AUTOSAR XML (schema 4-0-3)
standard types defined: Boolean, UInt8
package /AUTOSAR_Platform/DataConstrs
  range DC_Boolean: raw 0..1
  range DC_UInt8: raw 0..255
package /PATAC/EEPROM/BaseData
  base type PJB_EEP_Uint8: category=FIXED_LENGTH, base-type-size=8, base-type-encoding=NONE, native-declaration=unsigned char
package /PATAC/EEPROM/ImplementationDataType
  impl type EEP_Uint8: category=VALUE, base-type=PJB_EEP_Uint8, sw-calibration-access=READ-ONLY, type-emitter=RTE
package /PATAC/MSM/ComponentTypes
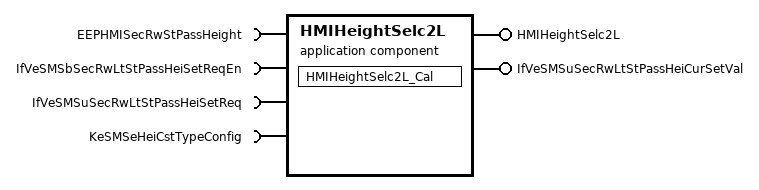
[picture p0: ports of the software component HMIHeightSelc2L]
  application sw component type HMIHeightSelc2L
    provide port HMIHeightSelc2L: server-com-spec{operation=Cal, queue-length=1}, provided-interface=HMIHeightSelc2L
    provide port IfVeSMSuSecRwLtStPassHeiCurSetVal: nonqueued-sender-com-spec{data-element=IfVeSMSuSecRwLtStPassHeiCurSetVal/Val, init-value=0}, provided-interface=IfVeSMSuSecRwLtStPassHeiCurSetVal
    4 x require port:
      EEPHMISecRwStPassHeight: required-com-specs=[Get, Set], required-interface=EEPHMISecRwStPassHeight
      IfVeSMSbSecRwLtStPassHeiSetReqEn: nonqueued-receiver-com-spec{data-element=IfVeSMSbSecRwLtStPassHeiSetReqEn/Val, filter=data-filter-type=ALWAYS, init-value=0}, required-interface=IfVeSMSbSecRwLtStPassHeiSetReqEn
      IfVeSMSuSecRwLtStPassHeiSetReq: nonqueued-receiver-com-spec{data-element=IfVeSMSuSecRwLtStPassHeiSetReq/Val, filter=data-filter-type=ALWAYS, init-value=0}, required-interface=IfVeSMSuSecRwLtStPassHeiSetReq
      KeSMSeHeiCstTypeConfig: parameter-require-com-spec{init-value=0, parameter=Val}, required-interface=KeSMSeHeiCstTypeConfig
    behavior HMIHeightSelc2L_InternalBehavior
      operation invoked event OIT_HMIHeightSelc2L_Cal_HMIHeightSelc2L_Cal: start-on-event=HMIHeightSelc2L_Cal, operation=HMIHeightSelc2L.Cal
      runnable HMIHeightSelc2L_Cal
        data-receive-point-by-arguments:
          access REC_IfVeSMSbSecRwLtStPassHeiSetReqEn_Val: accessed-variable=IfVeSMSbSecRwLtStPassHeiSetReqEn.Val
          access REC_IfVeSMSuSecRwLtStPassHeiSetReq_Val: accessed-variable=IfVeSMSuSecRwLtStPassHeiSetReq.Val
        data-send-points:
          access SEND_IfVeSMSuSecRwLtStPassHeiCurSetVal_Val: accessed-variable=IfVeSMSuSecRwLtStPassHeiCurSetVal.Val
        parameter access PA_KeSMSeHeiCstTypeConfig_Val: accessed-parameter=KeSMSeHeiCstTypeConfig.Val
        sync call SC_EEPHMISecRwStPassHeight_Get: operation=EEPHMISecRwStPassHeight.Get, timeout=0
        sync call SC_EEPHMISecRwStPassHeight_Set: operation=EEPHMISecRwStPassHeight.Set, timeout=0
  swc implementation HMIHeightSelc2L_Implementation: behavior=HMIHeightSelc2L_InternalBehavior
    code-descriptors:
      code Default: artifact-descriptors=autosar-engineering-object={short-label=Default, category=SWSRC}
package /PATAC/MSM/ModeAdjust/CalPortInterface
  parameter interface KeSMSeHeiCstTypeConfig
    parameter data prototype Val: sw-calibration-access=READ-WRITE, type=UInt8
package /PATAC/MSM/ModeAdjust/PortInterface
  client server interface EEPHMISecRwStPassHeight
    operation Get
      arg arg: type=EEP_Uint8, direction=OUT, server-argument-impl-policy=USE-ARGUMENT-TYPE
    operation Set
      arg arg: type=EEP_Uint8, direction=IN, server-argument-impl-policy=USE-ARGUMENT-TYPE
  client server interface HMIHeightSelc2L
    operation Cal
  sender receiver interface IfVeSMSbSecRwLtStPassHeiSetReqEn: invalidation-policy{data-element=IfVeSMSbSecRwLtStPassHeiSetReqEn/Val, handle-invalid=DONT-INVALIDATE}
    data Val: type=Boolean
  sender receiver interface IfVeSMSuSecRwLtStPassHeiCurSetVal: invalidation-policy{data-element=IfVeSMSuSecRwLtStPassHeiCurSetVal/Val, handle-invalid=DONT-INVALIDATE}
    data Val: type=UInt8
  sender receiver interface IfVeSMSuSecRwLtStPassHeiSetReq: invalidation-policy{data-element=IfVeSMSuSecRwLtStPassHeiSetReq/Val, handle-invalid=DONT-INVALIDATE}
    data Val: type=UInt8
